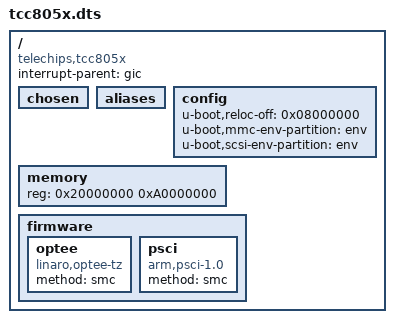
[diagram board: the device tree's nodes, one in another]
// SPDX-License-Identifier: (GPL-2.0-or-later OR MIT)
/*
 * Copyright (C) 2023 Telechips Inc.
 */

/ {
	compatible = "telechips,tcc805x";
	interrupt-parent = <&gic>;
	#address-cells = <1>;
	#size-cells = <1>;

	chosen: chosen {};
	aliases: aliases {};

	config: config {
		u-boot,reloc-off = <0x08000000>;
		u-boot,mmc-env-partition = "env";
		u-boot,scsi-env-partition = "env";
	};

	memory: memory {
		device_type = "memory";
		reg = <0x20000000 0xA0000000>;
	};

	firmware: firmware {
		optee: optee {
			compatible = "linaro,optee-tz";
			method = "smc";
		};

		psci: psci {
			compatible = "arm,psci-1.0";
			method = "smc";
		};
	};
};

#include "tcc805x-cpu.dtsi"
#include "tcc805x-clk.dtsi"
#include "tcc805x-gpio.dtsi"
#include "tcc805x-uart.dtsi"
#include "tcc805x-usb.dtsi"
#include "tcc805x-mbox.dtsi"
#include "tcc805x-scfw.dtsi"
#include "tcc805x-mmc.dtsi"
#include "tcc805x-ufs.dtsi"
#include "tcc805x-timer.dtsi"
#include "tcc805x-adc.dtsi"
#include "tcc805x-spi.dtsi"
#include "tcc805x-i2c.dtsi"
#include "tcc805x-pwm.dtsi"
#include "tcc805x-pcie.dtsi"
#include "tcc805x-hsmfw.dtsi"
